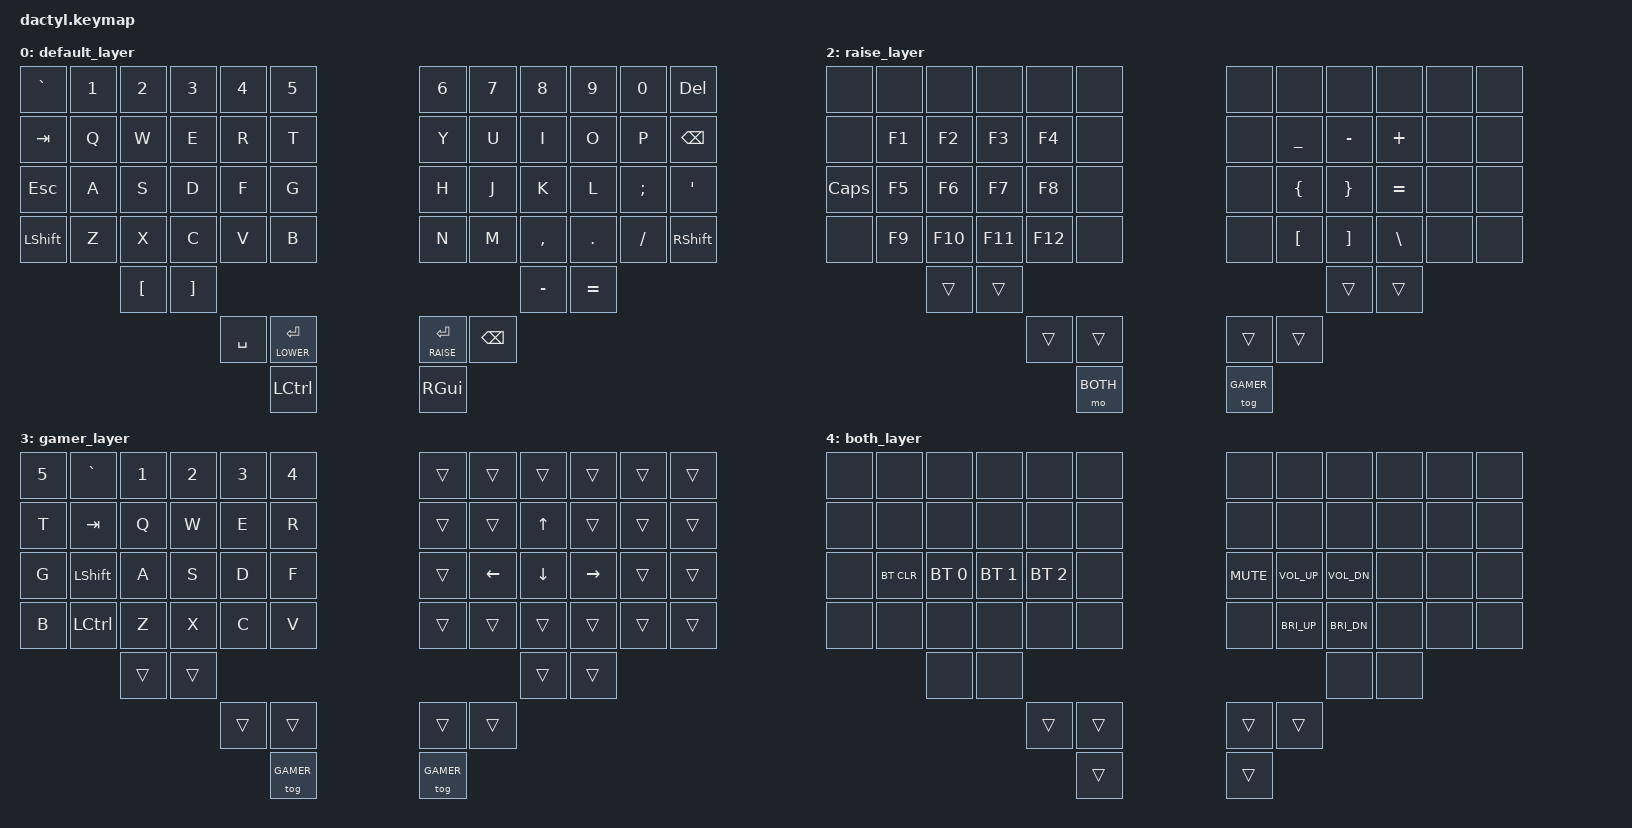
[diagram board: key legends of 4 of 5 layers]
#include <behaviors.dtsi>
#include <dt-bindings/zmk/keys.h>
#include <dt-bindings/zmk/bt.h>

#define DEFAULT 0
#define LOWER 1
#define RAISE 2
#define GAMER 3
#define BOTH 4

/ {
    keymap {
        compatible = "zmk,keymap";

        default_layer {
          bindings = <
    &kp GRAVE  &kp N1 &kp N2    &kp N3  &kp N4    &kp N5                                     &kp N6          &kp N7    &kp N8    &kp N9    &kp N0    &kp DEL
    &kp TAB    &kp Q  &kp W     &kp E   &kp R     &kp T                                      &kp Y           &kp U     &kp I     &kp O     &kp P     &kp BSPC
    &kp ESC    &kp A  &kp S     &kp D   &kp F     &kp G                                      &kp H           &kp J     &kp K     &kp L     &kp SEMI  &kp SQT 
    &kp LSHIFT &kp Z  &kp X     &kp C   &kp V     &kp B                                      &kp N           &kp M     &kp COMMA &kp DOT   &kp SLASH &kp RSHIFT
                      &kp LBKT  &kp RBKT                                                                               &kp MINUS &kp EQUAL
                                        &kp SPACE &lt LOWER ENTER                           &lt RAISE ENTER &kp BSPC 
                                                  &kp LCTRL                                 &kp RGUI 
          >;
        };

        lower_layer { // numbers & fctn keys
          bindings = <
    &none  &none      &none    &none      &kp FSLH &kp STAR                           &none    &none     &none     &none     &none    &none   
    &none  &kp N1     &kp N2   &kp N3     &kp N4   &kp MINUS                          &none    &kp F1    &kp F2    &kp F3    &kp F4   &none   
    &none  &kp N5     &kp N6   &kp N7     &kp N8   &kp PLUS                           &none    &kp F5    &kp F6    &kp F7    &kp F8   &none
    &none  &kp N9     &kp N0   &kp GRAVE  &kp DEL  &kp ENTER                          &none    &kp F9    &kp F10   &kp F11   &kp F12  &none
                       &kp BSLH &kp PIPE                                                                  &trans    &trans 
                                        &trans      &trans  &tog GAMER      &trans     &trans    &trans
                                                    &trans  &trans          &mo BOTH   &trans
          >;
        };

        raise_layer { // symbols and programming stuff
          bindings = <
    &none     &none     &none   &none   &none   &none                                     &none    &none      &none       &none     &none   &none   
    &none     &kp F1    &kp F2  &kp F3  &kp F4  &none                                     &none    &kp UNDER  &kp MINUS   &kp PLUS  &none   &none   
    &kp CAPS  &kp F5    &kp F6  &kp F7  &kp F8  &none                                     &none    &kp LBRC   &kp RBRC    &kp EQUAL &none   &none 
    &none     &kp F9    &kp F10 &kp F11 &kp F12 &none                                     &none    &kp LBKT   &kp RBKT    &kp BSLH  &none   &none   
                        &trans  &trans                                                                        &trans      &trans 
                                        &trans  &trans                                    &trans   &trans
                                                &mo BOTH                                  &tog GAMER
          >;
        };

        gamer_layer { // remap to have wasd on esdf for ergo and games that don't allow remapping
          bindings = <
    &kp N5  &kp GRAVE  &kp N1   &kp N2     &kp N3  &kp N4                              &trans    &trans     &trans      &trans    &trans   &trans   
    &kp T   &kp TAB    &kp Q    &kp W      &kp E   &kp R                               &trans    &trans     &kp UP      &trans    &trans   &trans   
    &kp G   &kp LSHIFT &kp A    &kp S      &kp D   &kp F                               &trans    &kp LEFT   &kp DOWN    &kp RIGHT &trans   &trans
    &kp B   &kp LCTRL  &kp Z    &kp X      &kp C   &kp V                               &trans    &trans     &trans      &trans    &trans   &trans   
                       &trans   &trans                                                                      &trans      &trans 
                                           &trans  &trans                              &trans    &trans
                                                   &tog GAMER                          &tog GAMER
          >;
        };

        both_layer { //  bluetooth, audio, mouse, other settings stuff
          bindings = <
    &none  &none       &none         &none         &none         &none                     &none        &none         &none         &none   &none   &none
    &none  &none       &none         &none         &none         &none                     &none        &none         &none         &none   &none   &none
    &none  &bt BT_CLR  &bt BT_SEL 0  &bt BT_SEL 1  &bt BT_SEL 2  &none                     &kp C_MUTE   &kp C_VOL_UP  &kp C_VOL_DN  &none   &none   &none
    &none  &none       &none         &none         &none         &none                     &none        &kp C_BRI_UP  &kp C_BRI_DN  &none   &none   &none   
                       &none         &none                                                                            &none         &none 
                                                   &trans  &trans                          &trans    &trans
                                                           &trans                          &trans
          >;
        };
    };
};
